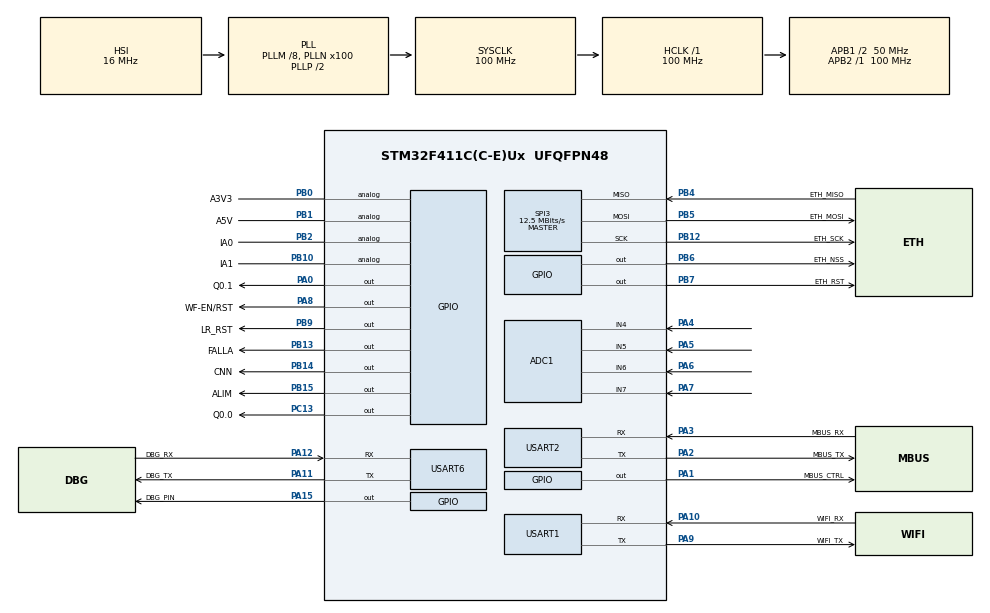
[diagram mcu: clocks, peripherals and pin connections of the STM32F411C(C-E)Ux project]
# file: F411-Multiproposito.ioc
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ADC1.Channel-0\#ChannelRegularConversion=ADC_CHANNEL_4
ADC1.NbrOfConversionFlag=1
ADC1.Rank-0\#ChannelRegularConversion=1
ADC1.SamplingTime-0\#ChannelRegularConversion=ADC_SAMPLETIME_3CYCLES
ADC1.master=1
Mcu.Family=STM32F4
Mcu.Name=STM32F411C(C-E)Ux
Mcu.Package=UFQFPN48
NVIC.PriorityGroup=NVIC_PRIORITYGROUP_4
NVIC.TIM2_IRQn=true\:0\:0\:false\:false\:true\:true\:true\:true
NVIC.TIM3_IRQn=true\:0\:0\:false\:false\:true\:true\:true\:true
NVIC.TIM4_IRQn=true\:0\:0\:false\:false\:true\:true\:true\:true
NVIC.USART1_IRQn=true\:0\:0\:false\:false\:true\:true\:true\:true
NVIC.USART2_IRQn=true\:0\:0\:false\:false\:true\:true\:true\:true
NVIC.USART6_IRQn=true\:0\:0\:false\:false\:true\:true\:true\:true
PA0-WKUP.GPIO_Label=Q0.1
PA0-WKUP.Signal=GPIO_Output
PA1.GPIO_Label=MBUS_CTRL
PA1.GPIO_ModeDefaultOutputPP=GPIO_MODE_OUTPUT_OD
PA1.GPIO_PuPd=GPIO_NOPULL
PA1.Signal=GPIO_Output
PA10.GPIO_Label=WIFI_RX
PA10.Mode=Asynchronous
PA10.Signal=USART1_RX
PA11.GPIO_Label=DBG_TX
PA11.Mode=Asynchronous
PA11.Signal=USART6_TX
PA12.GPIO_Label=DBG_RX
PA12.Mode=Asynchronous
PA12.Signal=USART6_RX
PA13.Mode=Trace_Asynchronous_SW
PA13.Signal=SYS_JTMS-SWDIO
PA14.Mode=Trace_Asynchronous_SW
PA14.Signal=SYS_JTCK-SWCLK
PA15.GPIO_Label=DBG_PIN
PA15.Signal=GPIO_Output
PA2.GPIO_Label=MBUS_TX
PA2.Mode=Asynchronous
PA2.Signal=USART2_TX
PA3.GPIO_Label=MBUS_RX
PA3.Mode=Asynchronous
PA3.Signal=USART2_RX
PA4.Signal=ADCx_IN4
PA5.Signal=ADCx_IN5
PA6.Signal=ADCx_IN6
PA7.Signal=ADCx_IN7
PA8.GPIO_Label=WF-EN/RST
PA8.Signal=GPIO_Output
PA9.GPIO_Label=WIFI_TX
PA9.Mode=Asynchronous
PA9.Signal=USART1_TX
PB0.GPIO_Label=A3V3
PB0.Signal=GPIO_Analog
PB1.GPIO_Label=A5V
PB1.Signal=GPIO_Analog
PB10.GPIO_Label=IA1
PB10.Signal=GPIO_Analog
PB12.GPIO_Label=ETH_SCK
PB12.Mode=Full_Duplex_Master
PB12.Signal=SPI3_SCK
PB13.GPIO_Label=FALLA
PB13.Signal=GPIO_Output
PB14.GPIO_Label=CNN
PB14.Signal=GPIO_Output
PB15.GPIO_Label=ALIM
PB15.Signal=GPIO_Output
PB2.GPIO_Label=IA0
PB2.Signal=GPIO_Analog
PB3.Mode=Trace_Asynchronous_SW
PB3.Signal=SYS_JTDO-SWO
PB4.GPIO_Label=ETH_MISO
PB4.Mode=Full_Duplex_Master
PB4.Signal=SPI3_MISO
PB5.GPIO_Label=ETH_MOSI
PB5.Mode=Full_Duplex_Master
PB5.Signal=SPI3_MOSI
PB6.GPIO_Label=ETH_NSS
PB6.Signal=GPIO_Output
PB7.GPIO_Label=ETH_RST
PB7.Signal=GPIO_Output
PB9.GPIO_Label=LR_RST
PB9.PinState=GPIO_PIN_RESET
PB9.Signal=GPIO_Output
PC13-ANTI_TAMP.GPIO_Label=Q0.0
PC13-ANTI_TAMP.Signal=GPIO_Output
PC14-OSC32_IN.Mode=LSE-External-Oscillator
PC14-OSC32_IN.Signal=RCC_OSC32_IN
PC15-OSC32_OUT.Mode=LSE-External-Oscillator
PC15-OSC32_OUT.Signal=RCC_OSC32_OUT
PH0\ -\ OSC_IN.Mode=HSE-External-Oscillator
PH0\ -\ OSC_IN.Signal=RCC_OSC_IN
PH1\ -\ OSC_OUT.Mode=HSE-External-Oscillator
PH1\ -\ OSC_OUT.Signal=RCC_OSC_OUT
ProjectManager.HeapSize=0x200
ProjectManager.StackSize=0x400
ProjectManager.TargetToolchain=STM32CubeIDE
RCC.48MHZClocksFreq_Value=50000000
RCC.AHBFreq_Value=100000000
RCC.APB1CLKDivider=RCC_HCLK_DIV2
RCC.APB1Freq_Value=50000000
RCC.APB1TimFreq_Value=100000000
RCC.APB2Freq_Value=100000000
RCC.APB2TimFreq_Value=100000000
RCC.CortexFreq_Value=100000000
RCC.HCLKFreq_Value=100000000
RCC.HSE_VALUE=25000000
RCC.HSI_VALUE=16000000
RCC.PLLM=8
RCC.PLLN=100
RCC.SYSCLKFreq_VALUE=100000000
RCC.SYSCLKSource=RCC_SYSCLKSOURCE_PLLCLK
RCC.VCOOutputFreq_Value=200000000
SH.ADCx_IN4.0=ADC1_IN4,IN4
SH.ADCx_IN5.0=ADC1_IN5,IN5
SH.ADCx_IN6.0=ADC1_IN6,IN6
SH.ADCx_IN7.0=ADC1_IN7,IN7
SPI3.BaudRatePrescaler=SPI_BAUDRATEPRESCALER_4
SPI3.CalculateBaudRate=12.5 MBits/s
SPI3.Direction=SPI_DIRECTION_2LINES
SPI3.Mode=SPI_MODE_MASTER
SPI3.VirtualType=VM_MASTER
TIM2.AutoReloadPreload=TIM_AUTORELOAD_PRELOAD_ENABLE
TIM2.Channel-Output\ Compare1\ No\ Output=TIM_CHANNEL_1
TIM2.OCMode_1=TIM_OCMODE_INACTIVE
TIM2.Period=20000
TIM2.Prescaler=1000
TIM3.AutoReloadPreload=TIM_AUTORELOAD_PRELOAD_ENABLE
TIM3.Channel-Output\ Compare1\ No\ Output=TIM_CHANNEL_1
TIM3.OCMode_1=TIM_OCMODE_INACTIVE
TIM3.Period=150
TIM3.Prescaler=100
TIM4.AutoReloadPreload=TIM_AUTORELOAD_PRELOAD_ENABLE
TIM4.Channel-Output\ Compare1\ No\ Output=TIM_CHANNEL_1
TIM4.OCMode_1=TIM_OCMODE_INACTIVE
TIM4.Period=150
TIM4.Prescaler=100
USART1.VirtualMode=VM_ASYNC
USART2.VirtualMode=VM_ASYNC
USART6.VirtualMode=VM_ASYNC
VP_RTC_VS_RTC_Activate.Mode=RTC_Enabled
VP_RTC_VS_RTC_Calendar.Mode=RTC_Calendar
VP_TIM2_VS_ClockSourceINT.Mode=Internal
VP_TIM2_VS_OPM.Mode=OPM_bit
VP_TIM2_VS_no_output1.Mode=Output Compare1 No Output
VP_TIM3_VS_ClockSourceINT.Mode=Internal
VP_TIM3_VS_OPM.Mode=OPM_bit
VP_TIM3_VS_no_output1.Mode=Output Compare1 No Output
VP_TIM4_VS_ClockSourceINT.Mode=Internal
VP_TIM4_VS_no_output1.Mode=Output Compare1 No Output
board=custom

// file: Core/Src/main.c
/* USER CODE BEGIN Header */
/**
  ******************************************************************************
  * @file           : main.c
  * @brief          : Main program body
  ******************************************************************************
  * @attention
  *
  * Copyright (c) 2024 STMicroelectronics.
  * All rights reserved.
  *
  * This software is licensed under terms that can be found in the LICENSE file
  * in the root directory of this software component.
  * If no LICENSE file comes with this software, it is provided AS-IS.
  *
  ******************************************************************************
  */
/* USER CODE END Header */
#include "main.h"

/* USER CODE BEGIN Includes */
#include "BKP_REG.h"
#include "string.h"
#include "stdio.h"
#include "ESP8266_Chelo.h"
#include "ModBUS_Chelo.h"
#include "STR_Chelo.h"
#include "ETH_W5100.h"
#include "http.h"
#include "string.h"
#include "RYLR896.h"
/* USER CODE END Includes */

/* USER CODE BEGIN PM */
#define ITM_Port32(n)   (*((volatile unsigned long *)(0xE0000000+4*n)))
#define UID_BASE_ADDRESS 0x1FFF7A10U
/* USER CODE END PM */

ADC_HandleTypeDef hadc1;

RTC_HandleTypeDef hrtc;

SPI_HandleTypeDef hspi3;

TIM_HandleTypeDef htim2;
TIM_HandleTypeDef htim3;
TIM_HandleTypeDef htim4;

UART_HandleTypeDef huart1;
UART_HandleTypeDef huart2;
UART_HandleTypeDef huart6;

/* USER CODE BEGIN PV */

struct LoRa lr;
struct WIFI wf;
struct W5100_SPI ETH;
struct MBUS mb_lr;
struct MBUS mb_eth;			// Instancia MODBus Ethernet
struct MBUS mb_wf;			// Instancia MODBus WiFi
struct BKP_REG NVS;

uint32_t dataRTC[20],
		 UID[3];

int		mseg=0, //conteo de milisegundos
	   	ms_ticks=0,
	   	min_ticks=0,
		MB_TOUT_ticks=0,
		ESP_ticks=0,
		wf_snd_flag_ticks=0,
		WF_SND_FLAG=0;

char EP_DATA[]="/logdata",//ENDPOINT[]="/tepelco",
	 EP_ERROR[]="/logerror",
	 EP_APROV[]="/aprovisionamiento",
	 EP_[]="/logdata";

uint16_t 	S0_get_size = 0,
			tx_mem_pointer=0,
			rx_mem_pointer=0,
			send_size=0;

uint8_t EN_UART1_TMR=0,
		EN_UART2_TMR=0,
		EN_UART6_TMR=0,
		ESP_conn=0,
		ESP_timeout=0,
		ESP_restart=0,
		ESP_HW_Init=0,
		ESP_REinit=0,			//Conteo de intentos de incializacion
		ESP_InitF=0,			//Flag de error por no encontrar la sentencia
		FLAG_UART1_WF=0,
		FLAG_UART2_485=0,
		FLAG_UART6=0,
		SYS_WEB_SERVER=0,
		SYS_WF_DEBUG_EN=1,
		SYS_DEBUG_EN=1,					//Muestra eventos de sistema  por ITM
		SYS_SPI_ETH_READ_EN=0,
		SYS_ETH_DBG_EN=0,
		SYS_saveConfigData=0,
		SYS_WIFI_UART_PASSTHROUGH=0,	//Vinvula el seria directo con el ESP8266, generando un puerto transparente
		spi_no_debug=0,
		spi_Data[64];

char	UART_RX_vect[4096],//UART_RX_vect[1024],
		UART2_RX_vect[512],
		UART6_RX_vect[4096],//UART6_RX_vect[512],
		UART_RX_vect_hld[4096],//UART_RX_vect_hld[1024],
		UART2_RX_vect_hld[1024],
		UART6_RX_vect_hld[4096],//UART6_RX_vect_hld[1024],
		CMP_VECT[]="\0",
		UART_RX_byte[2],
		UART2_RX_byte[2],
		UART6_RX_byte[2],
		APWFUID[65],
		dummyArray[20],
		post[512],
		body[512],

    	WEB_Salida[]="<!DOCTYPE html><html><body><h2>Datos salvados</h2></body></html>\r\n",

		WEB_Inicio_1[]="<!DOCTYPE html><html><body><h2>SetUp RIoT device</h2><form action=\"/192.168.4.1:80\">"
				"<p>IP SRVR</p><input type=\"number\" id=\"A\" name=\"A\" min=\"1\" max=\"254\"><input type=\"number\" id=\"B\" name=\"B\" min=\"0\" max=\"254\"><input type=\"number\" id=\"C\" name=\"C\" min=\"0\" max=\"254\"><input type=\"number\" id=\"D\" name=\"D\" min=\"1\" max=\"254\">"
				"<p>EP KEY</p><input type=\"number\" id=\"E\" name=\"E\" min=\"1\" max=\"4095\">"
				"<p>ETH IP</p><input type=\"number\" id=\"F\" name=\"F\" min=\"1\" max=\"254\"><input type=\"number\" id=\"G\" name=\"G\" min=\"0\" max=\"254\"><input type=\"number\" id=\"H\" name=\"H\" min=\"0\" max=\"254\"><input type=\"number\" id=\"I\" name=\"I\" min=\"1\" max=\"254\">"
				"<p>ETH MSK</p><input type=\"number\" id=\"J\" name=\"J\" min=\"0\" max=\"255\"><input type=\"number\" id=\"K\" name=\"K\" min=\"0\" max=\"255\"><input type=\"number\" id=\"L\" name=\"L\" min=\"0\" max=\"255\"><input type=\"number\" id=\"M\" name=\"M\" min=\"0\" max=\"255\">\r\n",

		WEB_Inicio_2[]="<p>ETH TRGT IP</p><input type=\"number\" id=\"J2\" name=\"J2\" min=\"1\" max=\"254\"><input type=\"number\" id=\"K2\" name=\"K2\" min=\"0\" max=\"254\"><input type=\"number\" id=\"L2\" name=\"L2\" min=\"0\" max=\"255\"><input type=\"number\" id=\"M2\" name=\"M2\" min=\"1\" max=\"254\">"
				"<p>ETH PRT</p><input type=\"number\" id=\"N\" name=\"N\" min=\"1\" max=\"65535\">"
				"<p>WF SSID</p><input type=\"text\" id=\"O\" name=\"O\" maxlength=\"28\" size=\"28\">"
				"<p>WF PSS</p><input type=\"password\" id=\"P\" name=\"P\" maxlength=\"12\" size=\"12\">"
				"<p>WF IP</p><input type=\"number\" id=\"Q\" name=\"Q\" min=\"1\" max=\"254\"><input type=\"number\" id=\"R\" name=\"R\" min=\"0\" max=\"255\"><input type=\"number\" id=\"S\" name=\"S\" min=\"0\" max=\"255\"><input type=\"number\" id=\"T\" name=\"T\" min=\"0\" max=\"254\">"
				"<p>WF MSK</p><input type=\"number\" id=\"U\" name=\"U\" min=\"1\" max=\"255\"><input type=\"number\" id=\"V\" name=\"V\" min=\"0\" max=\"255\"><input type=\"number\" id=\"W\" name=\"W\" min=\"0\" max=\"255\"><input type=\"number\" id=\"X\" name=\"X\" min=\"0\" max=\"255\">\r\n",

		WEB_Inicio_3[]="<p>WF PORT</p><input type=\"number\" id=\"Y\" name=\"Y\" min=\"1\" max=\"65535\">"
				"<p>MBUS REG START</p><input type=\"number\" id=\"MRS\" name=\"MRS\" min=\"0\" max=\"255\" step=\"1\" value=\"\">"
				"<p>MBUS ID Local</p><input type=\"number\" id=\"IL\" name=\"IL\" min=\"0\" max=\"255\" step=\"1\" value=\"\">"
				"<p>MBUS Code</p><input type=\"number\" id=\"MC\" name=\"MC\" min=\"3\" max=\"4\" step=\"1\" value=\"\">"
				"<p>MBUS ID SERVER</p><input type=\"number\" id=\"MIS\" name=\"MIS\" min=\"0\" max=\"255\" step=\"1\" value=\"\">"
				"<p>LoRa SRVR</p><input type=\"number\" id=\"Z\" name=\"Z\" min=\"1\" max=\"254\">"
				"<p>LoRa ADDR</p><input type=\"number\" id=\"Z2\" name=\"Z2\" min=\"1\" max=\"254\">"
				"<p>LoRa NID</p><input type=\"number\" id=\"0\" name=\"0\" min=\"0\" max=\"16\">"
				"<p>LoRa NCP</p><input type=\"number\" id=\"1\" name=\"1\" min=\"0\" max=\"16\">"
				"<p>LoRa BND</p><input type=\"number\" id=\"2\" name=\"2\" min=\"0\" max=\"55\">"
				"<input type=\"submit\" value=\"Salvar\"></form></body></html>\r\n";

		// 854 + 933 + 859

int 	dummy=0,
		dummy2=3,
		dummy3=27,
		dummy4=5,
		UART_RX_items=0,
		UART2_RX_items=0,
		UART6_RX_items=0,
		UART_RX_pos=0,
		UART2_RX_pos=0,
		UART6_RX_pos=0;

enum {
	TEPELCO,
	EFLUENTES,
	SANDBOX,
	PSEUDO,
	ESP3,
	ESP1,
	ESP2TH,
	POWERMETER,
	DISPONIBLE1,
	DISPONIBLE2,
	DISPONIBLE3,
	DISPONIBLE4,
	DISPONIBLE5,
	DISPONIBLE6,
	DISPONIBLE7,
	DISPONIBLE8,
	DISPONIBLE9,
	DISPONIBLE10
};

/* USER CODE END PV */

void SystemClock_Config(void);
static void MX_GPIO_Init(void);
static void MX_ADC1_Init(void);
static void MX_SPI3_Init(void);
static void MX_USART1_UART_Init(void);
static void MX_USART2_UART_Init(void);
static void MX_USART6_UART_Init(void);
static void MX_RTC_Init(void);
static void MX_TIM2_Init(void);
static void MX_TIM3_Init(void);
static void MX_TIM4_Init(void);

int main(void)
{

  /* USER CODE BEGIN 1 */

		//-----------------------1 Lectura de UID ------------------------//
		/* El Nro de UID se compone de 96 bits
		 * UID[0]=Coordenadas X e Y en el wafer
		 * UID[1]=Lote parcial + Nro de wafer
		 * UID[1]=Nro de Lote
		 * Por probabilidad vamos a tomar como UID a visualizar como AP los primeros 32 bits
		 */
			UID[0] = *(__IO uint32_t *)(UID_BASE_ADDRESS);
			UID[1] = *(__IO uint32_t *)(UID_BASE_ADDRESS + 4U);
			UID[2] = *(__IO uint32_t *)(UID_BASE_ADDRESS + 8U);
			INTOA(UID[0],dummyArray);
			strcpy(APWFUID,dummyArray);
			dummyArray[0]='-';
			dummyArray[1]='\0';
			strncat(APWFUID,dummyArray,strlen(dummyArray));
			dummyArray[0]='\0';
			INTOA(UID[1],dummyArray);
			strcpy(wf._WF_AP_Pass,dummyArray);
			strncat(APWFUID,dummyArray,strlen(dummyArray));
			strcpy(wf._WF_AP_SSID,"RIOT-");
			strncat(wf._WF_AP_SSID,APWFUID,strlen(APWFUID));

		//-----------------------0 Lectura de UID ------------------------//
		//----------------------1 ModBUS -----------------------//

			ModBUS_Config(&mb_lr);		//ETHERNET como cliente TCP envía  ModBUS
			mb_lr._mode = CLIENTE;
			ModBUS_Config(&mb_eth);		//ETHERNET como cliente TCP envía  ModBUS
			mb_eth._mode = CLIENTE;

		//----------------------0 ModBUS -----------------------//
		//-----------------------1 ETHERNET W5100 Environment-------------------------//

		//	GATEWAY ADDRESS
			ETH.GAR[0]=192;
			ETH.GAR[1]=168;
			ETH.GAR[2]=0;
			ETH.GAR[3]=1;
		//	SUBNET MASK
			ETH.SUBR[0]=255;
			ETH.SUBR[1]=255;
			ETH.SUBR[2]=255;
			ETH.SUBR[3]=0;
		//	MAC ADDRESS
			ETH.SHAR[0]=0x00;
			ETH.SHAR[1]=0x08;
			ETH.SHAR[2]=0xDC;
			ETH.SHAR[3]=0x00;
			ETH.SHAR[4]=0x00;
			ETH.SHAR[5]=0x01;
		//	IP ADDRESS
			ETH.SIPR[0]=192;
			ETH.SIPR[1]=168;
			ETH.SIPR[2]=0;
			ETH.SIPR[3]=34;//ETH.SIPR[3]=6,
		//  Socket RX memory
			ETH.RMSR=0x55;
		//  Socket TX memory
			ETH.TMSR=0x55;
		//  S0 Port Number
			ETH.S0_PORT[0]=0x01;
			ETH.S0_PORT[1]=0xF6;
		//	S0 Client IP ADDRESS
			ETH.S0_DIPR[0]=192;
			ETH.S0_DIPR[1]=168;
			ETH.S0_DIPR[2]=0;
			ETH.S0_DIPR[3]=3;//=3;
		//	S0 Client IP ADDRESS
			ETH.S0_DPORT[0]=0x01;
			ETH.S0_DPORT[1]=0xF6;

			ETH.gS0_RX_BASE = 0x6000;
			ETH.gS0_RX_MASK = 0x07FF;
			ETH.gS1_RX_BASE = 0x6800;
			ETH.gS1_RX_MASK = 0x07FF;
			ETH.gS2_RX_BASE = 0x7000;
			ETH.gS2_RX_MASK = 0x07FF;
			ETH.gS3_RX_BASE = 0x7800;
			ETH.gS3_RX_MASK = 0x07FF;
			ETH.gS0_TX_BASE = 0x4000;
			ETH.gS0_TX_MASK = 0x07FF;
			ETH.gS1_TX_BASE = 0x4800;
			ETH.gS1_TX_MASK = 0x07FF;
			ETH.gS2_TX_BASE = 0x5000;
			ETH.gS2_TX_MASK = 0x07FF;
			ETH.gS3_TX_BASE = 0x5800;
			ETH.gS3_TX_MASK = 0x07FF;

			ETH.S0_ENserver = 0;			//Actúa como servidor S0_ENserver=1 o cliente S0_ENserver=0

		//-----------------------0 ETHERNET W5100 Environment-------------------------//
		// -----------1 Seteo de módulo Ethernet W5100 ----------- //
			spi_no_debug=1;
			ETH.NSS_PORT=GPIOB;
			ETH.NSS_PIN=GPIO_PIN_6;
			ETH.SPI= &hspi3;
		// -----------0 Seteo de módulo Ethernet W5100 ----------- //

  /* USER CODE END 1 */

  /* MCU Configuration--------------------------------------------------------*/

  /* Reset of all peripherals, Initializes the Flash interface and the Systick. */
  HAL_Init();

  /* Configure the system clock */
  SystemClock_Config();

  /* Initialize all configured peripherals */
  MX_GPIO_Init();
  MX_ADC1_Init();
  MX_SPI3_Init();
  MX_USART1_UART_Init();
  MX_USART2_UART_Init();
  MX_USART6_UART_Init();
  MX_RTC_Init();
  MX_TIM2_Init();
  MX_TIM3_Init();
  MX_TIM4_Init();
  /* USER CODE BEGIN 2 */

  //------------------1 Habilitacion de dispositivos ---------------//

    HAL_GPIO_WritePin(GPIOB, LR_RST_Pin, GPIO_PIN_SET);		//Habilito LoRa
    HAL_GPIO_WritePin(GPIOA, MBUS_CTRL_Pin, GPIO_PIN_RESET);	//Habilito 485 para RX
    HAL_GPIO_WritePin(GPIOA, WF_EN_RST_Pin, GPIO_PIN_SET);	//Habilito WiFi
    HAL_GPIO_WritePin(GPIOB, GPIO_PIN_7, SET);				//Habilito ETHERNET

  //------------------0 Habilitacion de dispositivos ---------------//
  //------------------1 Se visualiza SSID y AP ---------------//
	ITM0_Write("\r\n\r\n\r\n SYS-uC ID :",strlen("\r\n\r\n\r\n SYS-uC ID :"));
	ITM0_Write(APWFUID,strlen(APWFUID));
	ITM0_Write( "\r\n\r\n\r\n SYS-AP-SSID :", strlen("\r\n\r\n\r\n SYS-AP-SSID :"));
	ITM0_Write( wf._WF_AP_SSID, strlen(wf._WF_AP_SSID));
	ITM0_Write( "\r\n\r\n\r\n SYS-AP-PASS : ", strlen("\r\n\r\n\r\n SYS-AP-PASS : "));
	ITM0_Write( wf._WF_AP_Pass, strlen(wf._WF_AP_Pass));
	ITM0_Write("\r\n\r\n\r\n SYS-ARRANQUE",strlen("\r\n\r\n\r\n SYS-ARRANQUE"));
	if(SYS_DEBUG_EN==1)
		{
			HAL_UART_Transmit(&huart6, "\r\n\r\n\r\n SYS-AP-SSID :", strlen("\r\n\r\n\r\n SYS-AP-SSID :"), 100);
			HAL_UART_Transmit(&huart6, wf._WF_AP_SSID, strlen(wf._WF_AP_SSID), 100);
			HAL_UART_Transmit(&huart6, "\r\n\r\n\r\n SYS-AP-PASS : ", strlen("\r\n\r\n\r\n SYS-AP-PASS : "), 100);
			HAL_UART_Transmit(&huart6, wf._WF_AP_Pass, strlen(wf._WF_AP_Pass), 100);
			HAL_UART_Transmit(&huart6, "\r\n SYS-ARRANQUE", strlen("\r\n SYS-ARRANQUE"), 100);
		}
	//------------------0 Se visualiza SSID y AP ---------------//

  //------------------1 Revisión de datos guardados en memoria ---------------//
  HAL_UART_Receive_IT(&huart1,(uint8_t *)UART_RX_byte,1);
  if(BKP_RG_BYTE(&hrtc,READ,LORA,BAND,NVS._LORA_BAND)==0)
  {
	  createAccessPoint(&wf,&huart1);
	  SYS_saveConfigData=1;
	  while(SYS_saveConfigData==1)
	  {
		  if(FLAG_UART1_WF==1)
		  {
			dummy2=strlen(":GET /192.168.4.1:80?A=");
			if(FT_String_ND(UART_RX_vect_hld,&UART_RX_items,":GET /192.168.4.1:80?A=",&dummy2,wf._uartRCVD_tok,wf._n_tok,&dummy,wf._id_conn,wf._overflowVector,FIND)==1)
				{
					BKP_AP_EXTRACT(&NVS,UART_RX_vect_hld,UART_RX_items);	//Gurado los datos ingresado por la web a la estrucutra NVS
					ITM0_Write("\r\n SYS-Escritura de valores en registros de back up",strlen("\r\n SYS-Escritura de valores en registros de back up"));
					if(SYS_DEBUG_EN==1) HAL_UART_Transmit(&huart6, "\r\n SYS-Escritura de valores en registros de back up", strlen("\r\n SYS-Escritura de valores en registros de back up"), 100);
					BKP_REG_RW(&hrtc, WRITE, &NVS);							//Salvo los datos de la estrucutra NVS en los registros de BackUp
					BKP_REG_SHW(&NVS,&huart6,SYS_DEBUG_EN);					//Muestro los datos leídos de la estructura
					if(SYS_DEBUG_EN==1)
						{
						HAL_UART_Transmit(&huart6, "\r\n SYS-Datos recibidos de AP", strlen("\r\n SYS-Datos recibidos de AP"), 100);
					    HAL_UART_Transmit(&huart1, "AT+CIPSEND=0,66\r\n", strlen("AT+CIPSEND=0,66\r\n"), 100);
					    HAL_Delay(500);
					    HAL_UART_Transmit(&huart1, WEB_Salida, strlen(WEB_Salida), 100);
						HAL_Delay(100);
						HAL_UART_Transmit(&huart1, "AT+CIPCLOSE=0\r\n", strlen("AT+CIPCLOSE=0\r\n"), 100);
						}
					SYS_saveConfigData=0;
					SYS_SPI_ETH_READ_EN=1;
					FLAG_UART1_WF=0;
				}
				else{
					  dummy2=strlen("+IPD,0,");
					  if(FT_String_ND(UART_RX_vect_hld,&UART_RX_items,"+IPD,0,",&dummy2,wf._uartRCVD_tok,wf._n_tok,&dummy,wf._id_conn,wf._overflowVector,FIND)==1)
					  {
						  //------------------------ PAGINA WEB ------------------------ //
						  HAL_UART_Transmit(&huart1, "AT+CIPSEND=0,856\r\n", strlen("AT+CIPSEND=0,856\r\n"), 100);
						  HAL_Delay(300);
						  HAL_UART_Transmit(&huart1, WEB_Inicio_1, strlen(WEB_Inicio_1), 100);
						  HAL_Delay(300);
						  HAL_UART_Transmit(&huart1, "AT+CIPSEND=0,935\r\n", strlen("AT+CIPSEND=0,935\r\n"), 100);
						  HAL_Delay(300);
						  HAL_UART_Transmit(&huart1, WEB_Inicio_2, strlen(WEB_Inicio_2), 100);
						  HAL_Delay(300);
						  HAL_UART_Transmit(&huart1, "AT+CIPSEND=0,861\r\n", strlen("AT+CIPSEND=0,861\r\n"), 100);
						  HAL_Delay(300);
						  HAL_UART_Transmit(&huart1, WEB_Inicio_3, strlen(WEB_Inicio_3), 100);
						  HAL_Delay(300);
						  HAL_UART_Transmit(&huart1, "AT+CIPCLOSE=0\r\n", strlen("AT+CIPCLOSE=0\r\n"), 100);
						  HAL_Delay(10);
						  //------------------------ PAGINA WEB ------------------------ //
						  FLAG_UART1_WF=0;
						  }else
							  {
							  FLAG_UART1_WF=0;
							  }
					}
		  }
	  }
  }
  else{
		  ITM0_Write("\r\n SYS-Lectura de valores en registros de back up",strlen("\r\n SYS-Lectura de valores en registros de back up"));
		  if(SYS_DEBUG_EN==1) HAL_UART_Transmit(&huart6, "\r\n SYS-Lectura de valores en registros de back up", strlen("\r\n SYS-Lectura de valores en registros de back up"), 100);
		  BKP_REG_RW(&hrtc, READ, &NVS);
		  BKP_REG_SHW(&NVS,&huart6,SYS_DEBUG_EN);
  	  }
  //------------------0 Revisión de datos guardados en memoria ---------------//

  //------------------1 Inicializacion UART ---------------//
  HAL_UART_Receive_IT(&huart1,(uint8_t *)UART_RX_byte,1);
  HAL_UART_Receive_IT(&huart2,(uint8_t *)UART2_RX_byte,1);
  HAL_UART_Receive_IT(&huart6,(uint8_t *)UART6_RX_byte,1);
  ITM0_Write("\r\nPuerto serie en escucha",strlen("\r\nPuerto serie en escucha"));
  if(SYS_DEBUG_EN==1) HAL_UART_Transmit(&huart6, "\r\nPuerto serie en escucha", strlen("\r\nPuerto serie en escucha"), 100);
  //------------------0 Inicializacion UART ---------------//

  //------------------1 Inicializacion ETHERNET ---------------//
  if(SYS_ETH_DBG_EN==1) ITM0_Write("\r\n SET-UP W5100 \r\n",strlen("\r\n SET-UP W5100 \r\n"));
  eth_init(&ETH);
  eth_socket_init(&ETH,0);
  SYS_SPI_ETH_READ_EN=1;
  //------------------0 Inicializacion ETHERNET ---------------//
  //------------------1 Inicializacion WIFI ---------------//

  	Inicializar(&wf); 									//Borra todos los registros de la estructura
  	wf.RESET_PORT=GPIOA;
  	wf.RESET_PIN=WF_EN_RST_Pin;
	strcpy(wf._WF_Net, NVS._WIFI_SSID);						//Nombre de la red WIFI  a conectar Fibertel WiFi967 2.4GHz
	strcpy(wf._WF_Pass, NVS._WIFI_PASS);						//Password de la red WIFI
	strcpy(wf._TCP_Remote_Server_IP, NVS._SERVER);		//char _TCP_Remote_Server_IP[16];		//IP del Servidor TCP
	strcpy(wf._TCP_Remote_Server_Port, NVS._WIFI_PORT);		//char _TCP_Remote_Server_Port[16];			//Puerto del Servidor TCP
	/*strcpy(wf._TCP_Local_Server_IP, TCP_SERVER_LOCAL);
	strcpy(wf._TCP_Local_Server_GWY, TCP_SERVER_LOCAL_GWY);
	strcpy(wf._TCP_Local_Server_MSK, TCP_SERVER_LOCAL_MSK);
	strcpy(wf._TCP_Local_Server_Port, TCP_PORT_LOCAL);*/
	wf._TCP_Local_Server_EN=0;							//Habilito el Servidor Local
	wf._estado_conexion=100;//Si no se define no arranca	//wf._estado_conexion=1;					//Arranco en WiFi Desconectado
	wf._automatizacion=WF_CONNECT_TCP;//wf._automatizacion=WF_SEND;//
	wf._NO_IP=1;
	wf._DBG_EN=1;

  if(ESP8266_HW_Init(&huart1)==1)
  {
	  ESP_HW_Init=1;
	  if (wf._DBG_EN==1) ITM0_Write("\r\n ESP HW Init OK\r\n",19);
	  if (SYS_WF_DEBUG_EN==1) HAL_UART_Transmit_IT(&huart6,"\r\n ESP HW Init OK\r\n",strlen("\r\n ESP HW Init OK\r\n"));
  }
  else
  {
	  ESP_REinit=0;
	  ESP8266_HW_Reset(&wf); 				//Si no logra resetear con el comando de AT+RESTORE, pruebo el resete desde hardware
	  if(ESP8266_HW_Init(&huart1)==1)
	  {
		  ESP_HW_Init=1;
		  if (wf._DBG_EN==1) ITM0_Write("\r\n ESP HW Init OK\r\n",19);
		  if (SYS_WF_DEBUG_EN==1) HAL_UART_Transmit_IT(&huart2,"\r\n ESP HW Init OK\r\n",strlen("\r\n ESP HW Init OK\r\n"));
	  }
	  else
	  {
		  ESP_HW_Init=0;
		  if (wf._DBG_EN==1)  ITM0_Write("\r\n ESP HW Init Fail\r\n",24);
		  if (SYS_WF_DEBUG_EN==1) HAL_UART_Transmit_IT(&huart2,"\r\n ESP HW Init Fail\r\n",strlen("\r\n ESP HW Init Fail\r\n"));
	  }
  }

  HAL_Delay(1000);
  //------------------0 Inicializacion WIFI ---------------//

  /* USER CODE END 2 */

  /* Infinite loop */
  while (1)
  {

    /* USER CODE BEGIN 3 */

	 if (ESP_restart==1) //WRNNG Hardcoded RESET WIFI
		{
			ESP8266_HW_Reset(&wf);
			ITM0_Write("\r\nESP8266 Restart",strlen("\r\nESP8266 Restart"));
		}

	 if (ESP_HW_Init==1) //Si el módulo se inició correctamente
		{
			if((WF_SND_FLAG==1)&&(wf._TCP_Local_Server_EN==0)&&(wf._estado_conexion>=609)&&(ETH.S0_data_available))
			{	ETH.S0_data_available=0;
				wf_snd_flag_ticks=0;
				WF_SND_FLAG=0;
				if( httpPOST(	EP_DATA, NVS._SERVER,NVS._WIFI_PORT,
								ModBUS_F03_Read(&mb_eth,0),
								ModBUS_F03_Read(&mb_eth,1),
								ModBUS_F03_Read(&mb_eth,2),
								ModBUS_F03_Read(&mb_eth,3),
								ModBUS_F03_Read(&mb_eth,4),
								ModBUS_F03_Read(&mb_eth,5),
								ModBUS_F03_Read(&mb_eth,6),
								ModBUS_F03_Read(&mb_eth,7),
								ModBUS_F03_Read(&mb_eth,8),
								ModBUS_F03_Read(&mb_eth,9),
								ModBUS_F03_Read(&mb_eth,10),
								ModBUS_F03_Read(&mb_eth,11),
								ModBUS_F03_Read(&mb_eth,12),
								ModBUS_F03_Read(&mb_eth,13),
								ModBUS_F03_Read(&mb_eth,14),
								ModBUS_F03_Read(&mb_eth,15),
								SANDBOX,post, body, 512))
				{
							CopiaVector(wf._data2SND,post,strlen(post),0,'A');
							wf._n_D2SND=strlen(post);
							if(wf._automatizacion < WF_SEND)		// Send only with automation sent diasabled
							{
								EnviarDatos(&wf);
								wf._estado_conexion=TCP_SND_EN_CURSO;
							}
				}
			}
		}

	  if((FLAG_UART1_WF==1)||(ESP_timeout==1))
		  {
			  if(ESP_timeout==1)
			  {
				ESP_timeout=0;
			  }
			if(FLAG_UART1_WF==1)
				{
					CopiaVector(wf._uartRCVD,UART_RX_vect_hld,UART_RX_items,1,CMP_VECT);
					FLAG_UART1_WF=0;
				}

			  ITM0_Write("\r\nRX UART1",strlen("\r\nRX UART1"));

			  if (ESP_HW_Init==1) //Si el módulo se inició correctamente
				{
					  /*************** Copio y proceso info recibida ***************/
					  wf._n_orig=UART_RX_items;
					  CopiaVector(wf._uartRCVD,UART_RX_vect_hld,UART_RX_items,1,CMP_VECT);
					  ESP_conn=AT_ESP8266_ND(&wf);

					/*************** Si recibo datos y estan correctos me fijo que son ***************/

					if ((wf._new_data_rcv==1)&&(wf._estado_rcv_data==99))
					{

						CopiaVector(mb_wf._MBUS_RCVD,wf._dataRCV,wf._n_dataRCV,0,'A');
						mb_wf._n_MBUS_RCVD=wf._n_dataRCV;

						ModBUS(&mb_wf);

						CopiaVector(wf._data2SND,mb_wf._MBUS_2SND,mb_wf._n_MBUS_2SND,0,'A');
						wf._n_D2SND=mb_wf._n_MBUS_2SND;
						wf._new_data_rcv=0;//
						wf._send_data=1;
					}else
						{
							// DATA ERRONEA NO SE PROCESA
						}
				}

			  FLAG_UART1_WF=0;
		  }
	  if (ESP_HW_Init==1) //Si el módulo se inició correctamente
		{
			ESP_conn=WiFi_Conn_ND(&wf,&huart1,1);	//Tiene que ir en el main el chequeo es constante
		}

	  if(FLAG_UART2_485==1)
	  {
		  ITM0_Write("\r\nRX UART2",strlen("\r\nRX UART2"));
		  dummy3=strlen("PRUEBA DE RECEPCION VIA 485");
		  if(FT_String_ND(UART2_RX_vect_hld,&UART2_RX_items,"PRUEBA DE RECEPCION VIA 485",&dummy3,wf._uartRCVD_tok,wf._n_tok,&dummy,wf._id_conn,wf._overflowVector,FIND)==1)
		  {
			  HAL_GPIO_WritePin(GPIOA, MBUS_CTRL_Pin, GPIO_PIN_SET);	//Habilito 485 para TX
			  HAL_UART_Transmit(&huart2,"TX VIA RS-485\r\n", 15, 100);
			  HAL_GPIO_WritePin(GPIOA, MBUS_CTRL_Pin, GPIO_PIN_RESET);	//Habilito 485 para RX
		  }
		  FLAG_UART2_485=0;
	  }

	  if(FLAG_UART6==1)
	  {
		  ITM0_Write("\r\nRX UART6",strlen("\r\nRX UART6"));
		  dummy4=strlen("+RCV");
		  if(FT_String_ND(UART6_RX_vect_hld,&UART6_RX_items,"+RCV",&dummy4,wf._uartRCVD_tok,wf._n_tok,&dummy,wf._id_conn,wf._overflowVector,FIND)==1)
		  {
			  HAL_UART_Transmit(&huart6,"AT\r\n", 4, 100);
		  }
		  FLAG_UART6=0;
	  }

  }
  /* USER CODE END 3 */
}

void SystemClock_Config(void)
{
  RCC_OscInitTypeDef RCC_OscInitStruct = {0};
  RCC_ClkInitTypeDef RCC_ClkInitStruct = {0};

  /** Configure the main internal regulator output voltage
  */
  __HAL_RCC_PWR_CLK_ENABLE();
  __HAL_PWR_VOLTAGESCALING_CONFIG(PWR_REGULATOR_VOLTAGE_SCALE1);

  /** Initializes the RCC Oscillators according to the specified parameters
  * in the RCC_OscInitTypeDef structure.
  */
  RCC_OscInitStruct.OscillatorType = RCC_OSCILLATORTYPE_HSI|RCC_OSCILLATORTYPE_LSI;
  RCC_OscInitStruct.HSIState = RCC_HSI_ON;
  RCC_OscInitStruct.HSICalibrationValue = RCC_HSICALIBRATION_DEFAULT;
  RCC_OscInitStruct.LSIState = RCC_LSI_ON;
  RCC_OscInitStruct.PLL.PLLState = RCC_PLL_ON;
  RCC_OscInitStruct.PLL.PLLSource = RCC_PLLSOURCE_HSI;
  RCC_OscInitStruct.PLL.PLLM = 8;
  RCC_OscInitStruct.PLL.PLLN = 100;
  RCC_OscInitStruct.PLL.PLLP = RCC_PLLP_DIV2;
  RCC_OscInitStruct.PLL.PLLQ = 4;
  if (HAL_RCC_OscConfig(&RCC_OscInitStruct) != HAL_OK)
  {
    Error_Handler();
  }

  /** Initializes the CPU, AHB and APB buses clocks
  */
  RCC_ClkInitStruct.ClockType = RCC_CLOCKTYPE_HCLK|RCC_CLOCKTYPE_SYSCLK
                              |RCC_CLOCKTYPE_PCLK1|RCC_CLOCKTYPE_PCLK2;
  RCC_ClkInitStruct.SYSCLKSource = RCC_SYSCLKSOURCE_PLLCLK;
  RCC_ClkInitStruct.AHBCLKDivider = RCC_SYSCLK_DIV1;
  RCC_ClkInitStruct.APB1CLKDivider = RCC_HCLK_DIV2;
  RCC_ClkInitStruct.APB2CLKDivider = RCC_HCLK_DIV1;

  if (HAL_RCC_ClockConfig(&RCC_ClkInitStruct, FLASH_LATENCY_3) != HAL_OK)
  {
    Error_Handler();
  }
}

static void MX_ADC1_Init(void)
{

  ADC_ChannelConfTypeDef sConfig = {0};

  /** Configure the global features of the ADC (Clock, Resolution, Data Alignment and number of conversion)
  */
  hadc1.Instance = ADC1;
  hadc1.Init.ClockPrescaler = ADC_CLOCK_SYNC_PCLK_DIV4;
  hadc1.Init.Resolution = ADC_RESOLUTION_12B;
  hadc1.Init.ScanConvMode = DISABLE;
  hadc1.Init.ContinuousConvMode = DISABLE;
  hadc1.Init.DiscontinuousConvMode = DISABLE;
  hadc1.Init.ExternalTrigConvEdge = ADC_EXTERNALTRIGCONVEDGE_NONE;
  hadc1.Init.ExternalTrigConv = ADC_SOFTWARE_START;
  hadc1.Init.DataAlign = ADC_DATAALIGN_RIGHT;
  hadc1.Init.NbrOfConversion = 1;
  hadc1.Init.DMAContinuousRequests = DISABLE;
  hadc1.Init.EOCSelection = ADC_EOC_SINGLE_CONV;
  if (HAL_ADC_Init(&hadc1) != HAL_OK)
  {
    Error_Handler();
  }

  /** Configure for the selected ADC regular channel its corresponding rank in the sequencer and its sample time.
  */
  sConfig.Channel = ADC_CHANNEL_4;
  sConfig.Rank = 1;
  sConfig.SamplingTime = ADC_SAMPLETIME_3CYCLES;
  if (HAL_ADC_ConfigChannel(&hadc1, &sConfig) != HAL_OK)
  {
    Error_Handler();
  }

}

static void MX_RTC_Init(void)
{

  RTC_TimeTypeDef sTime = {0};
  RTC_DateTypeDef sDate = {0};

  /** Initialize RTC Only
  */
  hrtc.Instance = RTC;
  hrtc.Init.HourFormat = RTC_HOURFORMAT_24;
  hrtc.Init.AsynchPrediv = 127;
  hrtc.Init.SynchPrediv = 255;
  hrtc.Init.OutPut = RTC_OUTPUT_DISABLE;
  hrtc.Init.OutPutPolarity = RTC_OUTPUT_POLARITY_HIGH;
  hrtc.Init.OutPutType = RTC_OUTPUT_TYPE_OPENDRAIN;
  if (HAL_RTC_Init(&hrtc) != HAL_OK)
  {
    Error_Handler();
  }

  /** Initialize RTC and set the Time and Date
  */
  sTime.Hours = 0x0;
  sTime.Minutes = 0x0;
  sTime.Seconds = 0x0;
  sTime.DayLightSaving = RTC_DAYLIGHTSAVING_NONE;
  sTime.StoreOperation = RTC_STOREOPERATION_RESET;
  if (HAL_RTC_SetTime(&hrtc, &sTime, RTC_FORMAT_BCD) != HAL_OK)
  {
    Error_Handler();
  }
  sDate.WeekDay = RTC_WEEKDAY_MONDAY;
  sDate.Month = RTC_MONTH_JANUARY;
  sDate.Date = 0x1;
  sDate.Year = 0x0;

  if (HAL_RTC_SetDate(&hrtc, &sDate, RTC_FORMAT_BCD) != HAL_OK)
  {
    Error_Handler();
  }

}

static void MX_SPI3_Init(void)
{

  /* SPI3 parameter configuration*/
  hspi3.Instance = SPI3;
  hspi3.Init.Mode = SPI_MODE_MASTER;
  hspi3.Init.Direction = SPI_DIRECTION_2LINES;
  hspi3.Init.DataSize = SPI_DATASIZE_8BIT;
  hspi3.Init.CLKPolarity = SPI_POLARITY_LOW;
  hspi3.Init.CLKPhase = SPI_PHASE_1EDGE;
  hspi3.Init.NSS = SPI_NSS_SOFT;
  hspi3.Init.BaudRatePrescaler = SPI_BAUDRATEPRESCALER_4;
  hspi3.Init.FirstBit = SPI_FIRSTBIT_MSB;
  hspi3.Init.TIMode = SPI_TIMODE_DISABLE;
  hspi3.Init.CRCCalculation = SPI_CRCCALCULATION_DISABLE;
  hspi3.Init.CRCPolynomial = 10;
  if (HAL_SPI_Init(&hspi3) != HAL_OK)
  {
    Error_Handler();
  }

}

static void MX_TIM2_Init(void)
{

  TIM_ClockConfigTypeDef sClockSourceConfig = {0};
  TIM_MasterConfigTypeDef sMasterConfig = {0};
  TIM_OC_InitTypeDef sConfigOC = {0};

  htim2.Instance = TIM2;
  htim2.Init.Prescaler = 1000;
  htim2.Init.CounterMode = TIM_COUNTERMODE_UP;
  htim2.Init.Period = 20000;
  htim2.Init.ClockDivision = TIM_CLOCKDIVISION_DIV1;
  htim2.Init.AutoReloadPreload = TIM_AUTORELOAD_PRELOAD_ENABLE;
  if (HAL_TIM_Base_Init(&htim2) != HAL_OK)
  {
    Error_Handler();
  }
  sClockSourceConfig.ClockSource = TIM_CLOCKSOURCE_INTERNAL;
  if (HAL_TIM_ConfigClockSource(&htim2, &sClockSourceConfig) != HAL_OK)
  {
    Error_Handler();
  }
  if (HAL_TIM_OC_Init(&htim2) != HAL_OK)
  {
    Error_Handler();
  }
  if (HAL_TIM_OnePulse_Init(&htim2, TIM_OPMODE_SINGLE) != HAL_OK)
  {
    Error_Handler();
  }
  sMasterConfig.MasterOutputTrigger = TIM_TRGO_RESET;
  sMasterConfig.MasterSlaveMode = TIM_MASTERSLAVEMODE_DISABLE;
  if (HAL_TIMEx_MasterConfigSynchronization(&htim2, &sMasterConfig) != HAL_OK)
  {
    Error_Handler();
  }
  sConfigOC.OCMode = TIM_OCMODE_INACTIVE;
  sConfigOC.Pulse = 0;
  sConfigOC.OCPolarity = TIM_OCPOLARITY_HIGH;
  sConfigOC.OCFastMode = TIM_OCFAST_DISABLE;
  if (HAL_TIM_OC_ConfigChannel(&htim2, &sConfigOC, TIM_CHANNEL_1) != HAL_OK)
  {
    Error_Handler();
  }

}

static void MX_TIM3_Init(void)
{

  TIM_ClockConfigTypeDef sClockSourceConfig = {0};
  TIM_MasterConfigTypeDef sMasterConfig = {0};
  TIM_OC_InitTypeDef sConfigOC = {0};

  htim3.Instance = TIM3;
  htim3.Init.Prescaler = 100;
  htim3.Init.CounterMode = TIM_COUNTERMODE_UP;
  htim3.Init.Period = 150;
  htim3.Init.ClockDivision = TIM_CLOCKDIVISION_DIV1;
  htim3.Init.AutoReloadPreload = TIM_AUTORELOAD_PRELOAD_ENABLE;
  if (HAL_TIM_Base_Init(&htim3) != HAL_OK)
  {
    Error_Handler();
  }
  sClockSourceConfig.ClockSource = TIM_CLOCKSOURCE_INTERNAL;
  if (HAL_TIM_ConfigClockSource(&htim3, &sClockSourceConfig) != HAL_OK)
  {
    Error_Handler();
  }
  if (HAL_TIM_OC_Init(&htim3) != HAL_OK)
  {
    Error_Handler();
  }
  if (HAL_TIM_OnePulse_Init(&htim3, TIM_OPMODE_SINGLE) != HAL_OK)
  {
    Error_Handler();
  }
  sMasterConfig.MasterOutputTrigger = TIM_TRGO_RESET;
  sMasterConfig.MasterSlaveMode = TIM_MASTERSLAVEMODE_DISABLE;
  if (HAL_TIMEx_MasterConfigSynchronization(&htim3, &sMasterConfig) != HAL_OK)
  {
    Error_Handler();
  }
  sConfigOC.OCMode = TIM_OCMODE_INACTIVE;
  sConfigOC.Pulse = 0;
  sConfigOC.OCPolarity = TIM_OCPOLARITY_HIGH;
  sConfigOC.OCFastMode = TIM_OCFAST_DISABLE;
  if (HAL_TIM_OC_ConfigChannel(&htim3, &sConfigOC, TIM_CHANNEL_1) != HAL_OK)
  {
    Error_Handler();
  }

}

static void MX_TIM4_Init(void)
{

  TIM_ClockConfigTypeDef sClockSourceConfig = {0};
  TIM_MasterConfigTypeDef sMasterConfig = {0};
  TIM_OC_InitTypeDef sConfigOC = {0};

  htim4.Instance = TIM4;
  htim4.Init.Prescaler = 100;
  htim4.Init.CounterMode = TIM_COUNTERMODE_UP;
  htim4.Init.Period = 150;
  htim4.Init.ClockDivision = TIM_CLOCKDIVISION_DIV1;
  htim4.Init.AutoReloadPreload = TIM_AUTORELOAD_PRELOAD_ENABLE;
  if (HAL_TIM_Base_Init(&htim4) != HAL_OK)
  {
    Error_Handler();
  }
  sClockSourceConfig.ClockSource = TIM_CLOCKSOURCE_INTERNAL;
  if (HAL_TIM_ConfigClockSource(&htim4, &sClockSourceConfig) != HAL_OK)
  {
    Error_Handler();
  }
  if (HAL_TIM_OC_Init(&htim4) != HAL_OK)
  {
    Error_Handler();
  }
  sMasterConfig.MasterOutputTrigger = TIM_TRGO_RESET;
  sMasterConfig.MasterSlaveMode = TIM_MASTERSLAVEMODE_DISABLE;
  if (HAL_TIMEx_MasterConfigSynchronization(&htim4, &sMasterConfig) != HAL_OK)
  {
    Error_Handler();
  }
  sConfigOC.OCMode = TIM_OCMODE_INACTIVE;
  sConfigOC.Pulse = 0;
  sConfigOC.OCPolarity = TIM_OCPOLARITY_HIGH;
  sConfigOC.OCFastMode = TIM_OCFAST_DISABLE;
  if (HAL_TIM_OC_ConfigChannel(&htim4, &sConfigOC, TIM_CHANNEL_1) != HAL_OK)
  {
    Error_Handler();
  }

}

static void MX_USART1_UART_Init(void)
{

  huart1.Instance = USART1;
  huart1.Init.BaudRate = 115200;
  huart1.Init.WordLength = UART_WORDLENGTH_8B;
  huart1.Init.StopBits = UART_STOPBITS_1;
  huart1.Init.Parity = UART_PARITY_NONE;
  huart1.Init.Mode = UART_MODE_TX_RX;
  huart1.Init.HwFlowCtl = UART_HWCONTROL_NONE;
  huart1.Init.OverSampling = UART_OVERSAMPLING_16;
  if (HAL_UART_Init(&huart1) != HAL_OK)
  {
    Error_Handler();
  }

}

static void MX_USART2_UART_Init(void)
{

  huart2.Instance = USART2;
  huart2.Init.BaudRate = 115200;
  huart2.Init.WordLength = UART_WORDLENGTH_8B;
  huart2.Init.StopBits = UART_STOPBITS_1;
  huart2.Init.Parity = UART_PARITY_NONE;
  huart2.Init.Mode = UART_MODE_TX_RX;
  huart2.Init.HwFlowCtl = UART_HWCONTROL_NONE;
  huart2.Init.OverSampling = UART_OVERSAMPLING_16;
  if (HAL_UART_Init(&huart2) != HAL_OK)
  {
    Error_Handler();
  }

}

static void MX_USART6_UART_Init(void)
{

  huart6.Instance = USART6;
  huart6.Init.BaudRate = 115200;
  huart6.Init.WordLength = UART_WORDLENGTH_8B;
  huart6.Init.StopBits = UART_STOPBITS_1;
  huart6.Init.Parity = UART_PARITY_NONE;
  huart6.Init.Mode = UART_MODE_TX_RX;
  huart6.Init.HwFlowCtl = UART_HWCONTROL_NONE;
  huart6.Init.OverSampling = UART_OVERSAMPLING_16;
  if (HAL_UART_Init(&huart6) != HAL_OK)
  {
    Error_Handler();
  }

}

static void MX_GPIO_Init(void)
{
  GPIO_InitTypeDef GPIO_InitStruct = {0};

  /* GPIO Ports Clock Enable */
  __HAL_RCC_GPIOC_CLK_ENABLE();
  __HAL_RCC_GPIOH_CLK_ENABLE();
  __HAL_RCC_GPIOA_CLK_ENABLE();
  __HAL_RCC_GPIOB_CLK_ENABLE();

  /*Configure GPIO pin Output Level */
  HAL_GPIO_WritePin(Q0_0_GPIO_Port, Q0_0_Pin, GPIO_PIN_RESET);

  /*Configure GPIO pin Output Level */
  HAL_GPIO_WritePin(GPIOA, Q0_1_Pin|MBUS_CTRL_Pin|WF_EN_RST_Pin|DBG_PIN_Pin, GPIO_PIN_RESET);

  /*Configure GPIO pin Output Level */
  HAL_GPIO_WritePin(GPIOB, FALLA_Pin|CNN_Pin|ALIM_Pin|ETH_NSS_Pin
                          |ETH_RST_Pin|LR_RST_Pin, GPIO_PIN_RESET);

  /*Configure GPIO pin : Q0_0_Pin */
  GPIO_InitStruct.Pin = Q0_0_Pin;
  GPIO_InitStruct.Mode = GPIO_MODE_OUTPUT_PP;
  GPIO_InitStruct.Pull = GPIO_NOPULL;
  GPIO_InitStruct.Speed = GPIO_SPEED_FREQ_LOW;
  HAL_GPIO_Init(Q0_0_GPIO_Port, &GPIO_InitStruct);

  /*Configure GPIO pins : Q0_1_Pin WF_EN_RST_Pin DBG_PIN_Pin */
  GPIO_InitStruct.Pin = Q0_1_Pin|WF_EN_RST_Pin|DBG_PIN_Pin;
  GPIO_InitStruct.Mode = GPIO_MODE_OUTPUT_PP;
  GPIO_InitStruct.Pull = GPIO_NOPULL;
  GPIO_InitStruct.Speed = GPIO_SPEED_FREQ_LOW;
  HAL_GPIO_Init(GPIOA, &GPIO_InitStruct);

  /*Configure GPIO pin : MBUS_CTRL_Pin */
  GPIO_InitStruct.Pin = MBUS_CTRL_Pin;
  GPIO_InitStruct.Mode = GPIO_MODE_OUTPUT_OD;
  GPIO_InitStruct.Pull = GPIO_NOPULL;
  GPIO_InitStruct.Speed = GPIO_SPEED_FREQ_LOW;
  HAL_GPIO_Init(MBUS_CTRL_GPIO_Port, &GPIO_InitStruct);

  /*Configure GPIO pins : A3V3_Pin A5V_Pin IA0_Pin IA1_Pin */
  GPIO_InitStruct.Pin = A3V3_Pin|A5V_Pin|IA0_Pin|IA1_Pin;
  GPIO_InitStruct.Mode = GPIO_MODE_ANALOG;
  GPIO_InitStruct.Pull = GPIO_NOPULL;
  HAL_GPIO_Init(GPIOB, &GPIO_InitStruct);

  /*Configure GPIO pins : FALLA_Pin CNN_Pin ALIM_Pin ETH_NSS_Pin
                           ETH_RST_Pin LR_RST_Pin */
  GPIO_InitStruct.Pin = FALLA_Pin|CNN_Pin|ALIM_Pin|ETH_NSS_Pin
                          |ETH_RST_Pin|LR_RST_Pin;
  GPIO_InitStruct.Mode = GPIO_MODE_OUTPUT_PP;
  GPIO_InitStruct.Pull = GPIO_NOPULL;
  GPIO_InitStruct.Speed = GPIO_SPEED_FREQ_LOW;
  HAL_GPIO_Init(GPIOB, &GPIO_InitStruct);

}

/* USER CODE BEGIN 4 */

void SysTick_Handler(void)
{
  /* USER CODE BEGIN SysTick_IRQn 0 */
   mseg++;
   ms_ticks++;
   ESP_ticks++;

	if (mseg==500)
		{
		   HAL_GPIO_TogglePin(GPIOB, FALLA_Pin);
		   HAL_GPIO_TogglePin(GPIOB, CNN_Pin);
		   HAL_GPIO_TogglePin(GPIOB, ALIM_Pin);
		   mseg=0;
		}

	if(mb_eth._w_answer) MB_TOUT_ticks++;
	if ( mb_eth._w_answer && (mb_eth._timeout < MB_TOUT_ticks))
		{
			mb_eth._w_answer=0;
			MB_TOUT_ticks=0;
		}
	// ENVIO DATOS WF ---------------------------------------------------------------//

		if((wf._estado_conexion==609 || wf._estado_conexion==700)&&(wf._TCP_Local_Server_EN==0))  wf_snd_flag_ticks++;

		if(wf_snd_flag_ticks>=4000 && wf._ejecucion!=1 && wf._TCP_Local_Server_EN==0)
			{
			WF_SND_FLAG=1;		//Envío de datos cada 20 segs
			}

	// ENVIO DATOS WF ----------------------------------- ---------------------------//

	/**********************[ INICIO - EHTERNET WDG ] **********************/

		if(ETH.S0_status == 0)
		{
			ETH.ETH_WDG++;
			if (ETH.ETH_WDG>=64000) ETH.ETH_WDG=64000;		//Si alcanza valor límite lo dejo en 64000
		}

	/**********************[ FIN 	- EHTERNET WDG ] **********************/
   if (ms_ticks==300)
     {
   	ms_ticks=0;
   	min_ticks++;

   	HAL_GPIO_TogglePin(GPIOC, GPIO_PIN_13);

   	if(spi_no_debug)
   	  {
   	  if(SYS_SPI_ETH_READ_EN==1)
   	  {
   		 HAL_GPIO_TogglePin(GPIOA, DBG_PIN_Pin);
   	     ETH.S0_status=eth_rd_SOCKET_STAT(&ETH,0);

   		  switch(ETH.S0_status)	//Check Socket status
   	     {
   			 case SOCK_CLOSED :
   				 {
   					 if (SYS_ETH_DBG_EN == 1) {ITM0_Write("\r\nS0_SOCK_CLOSED \r\n",strlen("\r\nS0_SOCK_CLOSED \r\n"));}
   					 eth_wr_SOCKET_CMD(&ETH, 0 ,OPEN );
   					 // Si no tengo intento de ARP por 5 segundos vuelvo a inicializar
   					 if(ETH.ETH_WDG>=5000)
   					 {
   						 ETH.ETH_WDG=0;
   						 eth_init(&ETH);
   						 eth_socket_init(&ETH,0);
   					 }

   				 }
   			 break;
   			 case  SOCK_INIT :
   				 {
   					 if(ETH.S0_ENserver == 1)
   					 {
   						 if (SYS_ETH_DBG_EN == 1) {ITM0_Write("\r\nS0_SOCK_INIT \r\n",strlen("\r\nS0_SOCK_INIT \r\n"));}
   							eth_wr_SOCKET_CMD(&ETH, 0, LISTEN );
   							ETH.ETH_WDG=0;
   					 }
   					 else
   					 {
   						 	eth_wr_SOCKET_CMD(&ETH,0, CONNECT);																				//only for server
   						 	if (SYS_ETH_DBG_EN == 1)
   						 	{
   						 		ITM0_Write("\r\nETH-W5100-CONNECT\r\n",strlen("\r\nETH-W5100-CONNECT\r\n"));
   						 	}
   						 	ETH.ETH_WDG=0;
   					 }

   				 }
   			 break;
   			 case SOCK_LISTEN :
   				 {
   					 if (SYS_ETH_DBG_EN == 1) {ITM0_Write("\r\nS0_SOCK_LISTEN \r\n",strlen("\r\nS0_SOCK_LISTEN \r\n"));}
   					 ETH.ETH_WDG=0;
   				 }
   			 break;
   			 case SOCK_SYNSENT :
   				 {
   					 if (SYS_ETH_DBG_EN == 1) {ITM0_Write("\r\nS0_SOCK_SYNSENT \r\n",strlen("\r\nS0_SOCK_SYNSENT \r\n"));}
   					 ETH.ETH_WDG=0;
   				 }
   			 break;
   			 case SOCK_SYNRECV :
   				 {
   					 if (SYS_ETH_DBG_EN == 1) {ITM0_Write("\r\nS0_SOCK_SYNRECV \r\n",strlen("\r\nS0_SOCK_SYNRECV \r\n"));}
   					 ETH.ETH_WDG=0;
   				 }
   			 break;
   			 case SOCK_ESTABLISHED :
   				 {
   					 if (SYS_ETH_DBG_EN == 1) {ITM0_Write("\r\nS0_SOCK_ESTABLISHED \r\n",strlen("\r\nS0_SOCK_ESTABLISHED \r\n"));}
   					 ETH.ETH_WDG=0;

   					if (ETH.S0_ENserver == 1)  // Si el puerto Ethernet actúa como server (Recibe datos conexión mas pedido mbus
   					{

   							S0_get_size = SPI_ETH_REG(&ETH, S0_RX_SZ_ADDR_BASEHH,S0_RX_SZ_ADDR_BASEHL ,SPI_READ, spi_Data,2);
   							if(S0_get_size != 0x00)
   							{
   								eth_rd_SOCKET_DATA(&ETH,0,&rx_mem_pointer,S0_get_size); // read socket data
   								SPI_ETH_WR_REG_16(&ETH,S0_RX_RD0,rx_mem_pointer );		// write rx memory pointer
   								eth_wr_SOCKET_CMD(&ETH,0,RECV);							// write command to execute
   								while(eth_rd_SOCKET_CMD(&ETH,0))						// wait until end of command execution
   								{}

   								CopiaVector(mb_eth._MBUS_RCVD, ETH.data, S0_get_size, 0, 0 );
   								mb_eth._n_MBUS_RCVD=S0_get_size;

   								//if(S0_get_size > 0)	{ ETH.S0_data_available=1;}					//Flag data received

   								if(ModBUS_Check(mb_eth._MBUS_RCVD, mb_eth._n_MBUS_RCVD))		//Ckecks ModBUS type data
   								{
   									ModBUS(&mb_eth);										//ModBUS protocol execution
   									CopiaVector(ETH.data, mb_eth._MBUS_2SND, mb_eth._n_MBUS_2SND, 0, 0);
   								}
   								else
   								{
   									if (SYS_ETH_DBG_EN == 1) {ITM0_Write("\r\n NO MBUS \r\n",strlen("\r\n\r\n NO MBUS \r\n\r\n"));}
   								}

   								send_size=mb_eth._n_MBUS_2SND;  //ModBUS data qty

   								eth_wr_SOCKET_DATA(&ETH,0, &tx_mem_pointer, send_size);	// write socket data
   								SPI_ETH_WR_REG_16(&ETH,0x424,tx_mem_pointer);			// write tx memory pointer
   								eth_wr_SOCKET_CMD(&ETH,0,SEND);							// write command to execute
   								while(eth_rd_SOCKET_CMD(&ETH,0))						// wait until end of command execution
   								{}

   							}
   					}
   					else	// Puerto ethernet labura como esclavo, se conecta al server para pedir datos
   					{

   						if (mb_eth._w_answer==0)
   						{
   							//Si ya envié vuelvo a enviar

   							ETH.data[0]=0x00;
   							ETH.data[1]=0x00;
   							ETH.data[2]=0x00;
   							ETH.data[3]=0x00;
   							ETH.data[4]=0x00;
   							ETH.data[5]=0x06;
   							ETH.data[6]=0x01;
   							ETH.data[7]=0x03;
   							ETH.data[8]=0x00;
   							ETH.data[9]=0x00;
   							ETH.data[10]=0x00;
   							ETH.data[11]=0x0A;
   							send_size=12;

   							ModBUS_F03_Request(&mb_eth,0,15);
   							CopiaVector(ETH.data, mb_eth._MBUS_2SND, 12, 0, 0 );

   							eth_wr_SOCKET_DATA(&ETH,0, &tx_mem_pointer, send_size);	// write socket data
   							SPI_ETH_WR_REG_16(&ETH,0x424,tx_mem_pointer);			// write tx memory pointer
   							eth_wr_SOCKET_CMD(&ETH,0,SEND);							// write command to execute
   							while(eth_rd_SOCKET_CMD(&ETH,0))						// wait until end of command execution
   							{}
   							mb_eth._w_answer=1;	// Waiting answer flag
   							MB_TOUT_ticks=0;	// restart counting
   							if (SYS_ETH_DBG_EN == 1) {ITM0_Write("\r\n SENT MBUS REQ \r\n",strlen("\r\n\r\n SENT MBUS REQ \r\n\r\n"));}
   						}
   						else
   						{
   						S0_get_size = SPI_ETH_REG(&ETH, S0_RX_SZ_ADDR_BASEHH,S0_RX_SZ_ADDR_BASEHL ,SPI_READ, spi_Data,2);
   							if(S0_get_size != 0x00)
   							{
   								eth_rd_SOCKET_DATA(&ETH,0,&rx_mem_pointer,S0_get_size); // read socket data
   								SPI_ETH_WR_REG_16(&ETH,S0_RX_RD0,rx_mem_pointer );		// write rx memory pointer
   								eth_wr_SOCKET_CMD(&ETH,0,RECV);							// write command to execute
   								while(eth_rd_SOCKET_CMD(&ETH,0))						// wait until end of command execution
   								{}

   								CopiaVector(mb_eth._MBUS_RCVD, ETH.data, S0_get_size, 0, 0 );
   								mb_eth._n_MBUS_RCVD=S0_get_size;

   								//if(S0_get_size > 0)	{ ETH.S0_data_available=1;}

   								if(ModBUS_Check(mb_eth._MBUS_RCVD, mb_eth._n_MBUS_RCVD))		//Ckecks ModBUS type data
   									{
   										mb_eth._w_answer=0;  									//Si el mensaje recibido ya es modbus digo que ya recibi
   										MB_TOUT_ticks=0;
   										ModBUS(&mb_eth);										//ModBUS protocol execution
   										CopiaVector(ETH.swap, mb_eth._MBUS_RCVD, mb_eth._n_MBUS_RCVD, 0, 0);
   										CopiaVector(mb_wf._Holding_Registers, mb_eth._Holding_Registers, 64, 0, 0);
   										ETH.S0_data_available=1;	//Informa que se ha recibido un dato y es ModBUS
   										if (SYS_ETH_DBG_EN == 1)
   										{
   											HAL_UART_Transmit_IT(&huart2,"\r\nMBUS RCVD\r\n",strlen("\r\nMBUS RCVD\r\n"));
   											ITM0_Write("\r\n RCVD MBUS REQ \r\n",strlen("\r\n\r\n RCVD MBUS REQ \r\n\r\n"));
   										}
   									}
   									else
   										{
   										if (SYS_ETH_DBG_EN == 1) {ITM0_Write("\r\n NO MBUS \r\n",strlen("\r\n\r\n NO MBUS \r\n\r\n"));}
   										}

   							}
   						}
   					}
   				 }
   			 break;
   			 case SOCK_FIN_WAIT :
   				 {
   					 if (SYS_ETH_DBG_EN == 1) {ITM0_Write("\r\nS0_SOCK_FIN_WAIT \r\n",strlen("\r\nS0_SOCK_FIN_WAIT \r\n"));}
   					 ETH.ETH_WDG=0;
   				 }
   			 break;
   			 case SOCK_CLOSING :
   				 {
   					 if (SYS_ETH_DBG_EN == 1) {ITM0_Write("\r\nS0_SOCK_CLOSING \r\n",strlen("\r\nS0_SOCK_CLOSING \r\n"));}
   					 ETH.ETH_WDG=0;
   				 }
   			 break;
   			 case  SOCK_TIME_WAIT :
   				 {
   					 if (SYS_ETH_DBG_EN == 1) {ITM0_Write("\r\nS0_SOCK_TIME_WAIT \r\n",strlen("\r\nS0_SOCK_TIME_WAIT \r\n"));}
   					eth_wr_SOCKET_CMD(&ETH,0, DISCON );
   					while( SPI_ETH_REG(&ETH, S0_CR_ADDR_BASEH,S0_CR_ADDR_BASEL ,SPI_READ, spi_Data,1))
   					{}
   					ETH.ETH_WDG=0;
   				 }
   			 break;
   			 case SOCK_CLOSE_WAIT :
   				 {
   					 if (SYS_ETH_DBG_EN == 1) {ITM0_Write("\r\nS0_SOCK_CLOSE_WAIT \r\n",strlen("\r\nS0_SOCK_CLOSE_WAIT \r\n"));}
   					eth_wr_SOCKET_CMD(&ETH,0,DISCON );
   					while( SPI_ETH_REG(&ETH, S0_CR_ADDR_BASEH,S0_CR_ADDR_BASEL ,SPI_READ, spi_Data,1))
   					{}
   					ETH.ETH_WDG=0;
   				 }
   			 break;
   			 case SOCK_LAST_ACK :
   				 {
   					 if (SYS_ETH_DBG_EN == 1)
   					 {
   						 ITM0_Write("\r\nS0_SOCK_LAST_ACK \r\n",strlen("\r\nS0_SOCK_LAST_ACK \r\n"));
   					 }
   					 ETH.ETH_WDG=0;
   				 }
   			 break;
   			 case SOCK_UDP :
   				 {
   					 if (SYS_ETH_DBG_EN == 1){ ITM0_Write("\r\nS0_SOCK_UDP \r\n",strlen("\r\nS0_SOCK_UDP \r\n"));}
   					 ETH.ETH_WDG=0;
   				 }
   			 break;
   			 case  SOCK_IPRAW :
   				 {
   					 if (SYS_ETH_DBG_EN == 1) {ITM0_Write("\r\nS0_SOCK_IPRAW \r\n",strlen("\r\nS0_SOCK_IPRAW \r\n"));}
   					 ETH.ETH_WDG=0;
   				 }
   			 break;
   			 case  SOCK_MACRAW :
   				 {
   					 if (SYS_ETH_DBG_EN == 1) {ITM0_Write("\r\nS0_SOCK_MACRAW \r\n",strlen("\r\nS0_SOCK_MACRAW \r\n"));}
   					 ETH.ETH_WDG=0;
   				 }
   			 break;
   			 case SOCK_PPOE :
   				 {
   					 if (SYS_ETH_DBG_EN == 1) {ITM0_Write("\r\nS0_SOCK_PPOE \r\n",strlen("\r\nS0_SOCK_PPOE \r\n"));}
   					 ETH.ETH_WDG=0;
   				 }
   			 break;

   			 default:
   				 {

   				 }
   	     }
   	  }
   	  }else
   	  	  {
   		  SPI_ETH(&ETH);
   	  	  }
   	  if(min_ticks==2)//if(min_ticks==10)
   		  {
   		  	  min_ticks=0;  /* SETEO CADA 2 min*/
   		  }
     }
  /* USER CODE END SysTick_IRQn 0 */
  HAL_IncTick();
  /* USER CODE BEGIN SysTick_IRQn 1 */
	if(wf._estado_conexion==4)//Solo cuento cuando no estahaciendo otra cosa
	{
		//ticks++;
	}
	else
	{
		//ticks=0;
	}

if(wf._ejecucion==1)
	{
		if (ESP_timeout!=1)
		{
			if(wf._instruccion!=2) wf._ticks++;//-----------------------Solo cuento una vez reconcido el timeout, cuando entro al timeout no cuento
			if(wf._instruccion==2) wf._ticks2++;
		}

		if ((wf._instruccion!=2)&&(wf._ticks > 5500)) //if (wf._ticks > 5000)
		{
			ESP_timeout=1;
			if(huart1.Instance->CR1 == 0x200C)  //--------------------Evito error UART colgado
			{
				HAL_UART_Receive_IT(&huart1,(uint8_t *)UART_RX_byte,1);
				FLAG_UART1_WF=0; //OBS-VER Para que me vuelva a habilitar el timer
			}
		}
		if ((wf._instruccion==2)&&(wf._ticks2 > 20500)) //if (wf._ticks > 5000)
		{
			ESP_timeout=1;
			if(huart1.Instance->CR1 == 0x200C)  //--------------------Evito error UART colgado
			{
				HAL_UART_Receive_IT(&huart1,(uint8_t *)UART_RX_byte,1);
				FLAG_UART1_WF=0; //OBS-VER Para que me vuelva a habilitar el timer
			}
		}

	}
	else
	{
		wf._ticks=0;
	}
  /* USER CODE END SysTick_IRQn 1 */
}

void HAL_UART_RxCpltCallback(UART_HandleTypeDef *INTSERIE)
{

// WiFi	USART 1 TIMER2
	if(INTSERIE->Instance==USART1)
		 {
			UART_RX_vect[UART_RX_pos]=UART_RX_byte[0];
			UART_RX_pos++;
			//if(UART_RX_pos>=1022) UART_RX_pos=1022;
			if(UART_RX_pos>=4095) UART_RX_pos=4095;
			HAL_TIM_OC_Start_IT(&htim2, TIM_CHANNEL_1);//HAL_TIM_Base_Start_IT(&htim7);	//Habilito el timer
			TIM2->CNT=1;
			EN_UART1_TMR=1;	//Habilito Timeout de software
			HAL_UART_Receive_IT(INTSERIE,(uint8_t *)UART_RX_byte,1);
		 }
// MBUS USART2 TIMER3
	if(INTSERIE->Instance==USART2)
		 {
			UART2_RX_vect[UART2_RX_pos]=UART2_RX_byte[0];
			UART2_RX_pos++;
			if(UART2_RX_pos>=512) UART2_RX_pos=512;
			HAL_TIM_OC_Start_IT(&htim3, TIM_CHANNEL_1);//HAL_TIM_Base_Start_IT(&htim7);	//Habilito el timer
			TIM3->CNT=1;
			EN_UART2_TMR=1;	//Habilito Timeout de software
			HAL_UART_Receive_IT(INTSERIE,(uint8_t *)UART2_RX_byte,1);
		 }
// LoRa/debgg USART6 TIMER3
	if(INTSERIE->Instance==USART6)
		 {
			UART6_RX_vect[UART6_RX_pos]=UART6_RX_byte[0];
			UART6_RX_pos++;
			//if(UART6_RX_pos>=512) UART6_RX_pos=512;
			if(UART6_RX_pos>=4095) UART6_RX_pos=4095;
			HAL_TIM_OC_Start_IT(&htim4, TIM_CHANNEL_1);//HAL_TIM_Base_Start_IT(&htim7);	//Habilito el timer
			TIM4->CNT=1;
			EN_UART6_TMR=1;	//Habilito Timeout de software
			HAL_UART_Receive_IT(INTSERIE,(uint8_t *)UART6_RX_byte,1);
		 }
 }

void HAL_TIM_OC_DelayElapsedCallback(TIM_HandleTypeDef *TIMER)
{
// WiFi	USART 1 TIMER2
		if(TIMER->Instance==TIM2)
			{
				 HAL_TIM_OC_Stop_IT(TIMER, TIM_CHANNEL_1); //Paro el timer
				 FLAG_UART1_WF=1;
				 EN_UART1_TMR=0;
				 UART_RX_items=UART_RX_pos;
				 UART_RX_pos=0;
				 UART_RX_vect[4095]='\0';//UART_RX_vect[1022]='\0'; //Finalizo el vector a la fuerza ya que recibo hasta 124
				 CopiaVector(UART_RX_vect_hld,UART_RX_vect,UART_RX_items,1,CMP_VECT);
				 if(SYS_WIFI_UART_PASSTHROUGH==1) HAL_UART_Transmit_IT(&huart6, UART_RX_vect_hld, UART_RX_items);	//Reenvío la info a traves de UART6 solo si esta habilitado
				 HAL_UART_Receive_IT(&huart1,(uint8_t *)UART_RX_byte,1); //Habilito le recepcón de puerto serie al terminar
				 if (wf._DBG_EN==1)
				 {
					 ITM0_Write("\r\nData WIFI recibida = ",strlen("\r\nData WIFI recibida = "));
					 ITM0_Write((uint8_t *)UART_RX_vect_hld,UART_RX_items);
					 ITM0_Write("\r\n",strlen("\r\n"));
				 }
		}
// MBUS USART2 TIMER3
		if(TIMER->Instance==TIM3)
			{
				 HAL_TIM_OC_Stop_IT(TIMER, TIM_CHANNEL_1); //Paro el timer
				 HAL_GPIO_WritePin(GPIOA, GPIO_PIN_1, 0);
				 FLAG_UART2_485=1;
				 EN_UART2_TMR=0;
				 UART2_RX_items=UART2_RX_pos;
				 UART2_RX_pos=0;
				 UART2_RX_vect[512]='\0'; //Finalizo el vector a la fuerza ya que recibo hasta 124
				 CopiaVector(UART2_RX_vect_hld,UART2_RX_vect,UART2_RX_items,1,CMP_VECT);
				 HAL_UART_Receive_IT(&huart2,(uint8_t *)UART2_RX_byte,1); //Habilito le recepcón de puerto serie al terminar
				 if (wf._DBG_EN==1)
				 {
					 ITM0_Write("\r\nData MBUS recibida = ",strlen("\r\nData MUS recibida = "));
					 ITM0_Write((uint8_t *)UART2_RX_vect,UART2_RX_items);
					 ITM0_Write("\r\n",strlen("\r\n"));
				 }
		}

// LoRa/Debbg USART6 TIMER3
		if(TIMER->Instance==TIM4)
			{
				 HAL_TIM_OC_Stop_IT(TIMER, TIM_CHANNEL_1); //Paro el timer
				 HAL_GPIO_WritePin(GPIOA, GPIO_PIN_1, 0);
				 FLAG_UART6=1;
				 EN_UART6_TMR=0;
				 UART6_RX_items=UART6_RX_pos;
				 UART6_RX_pos=0;
				 UART6_RX_vect[4095]='\0'; //UART6_RX_vect[512]='\0'; //Finalizo el vector a la fuerza ya que recibo hasta 124
				 CopiaVector(UART6_RX_vect_hld,UART6_RX_vect,UART6_RX_items,1,CMP_VECT);
				 if(SYS_WIFI_UART_PASSTHROUGH==1) HAL_UART_Transmit_IT(&huart1, UART6_RX_vect_hld, UART6_RX_items);	//Reenvío la info a traves de UART1 solo si esta habilitado
				 HAL_UART_Receive_IT(&huart6,(uint8_t *)UART6_RX_byte,1); //Habilito le recepcón de puerto serie al terminar
				 if (wf._DBG_EN==1)
				 {
					 ITM0_Write("\r\nData LoRa recibida = ",strlen("\r\nData LoRa recibida = "));
					 ITM0_Write((uint8_t *)UART6_RX_vect,UART6_RX_items);
					 ITM0_Write("\r\n",strlen("\r\n"));
				 }
		}
}

void HAL_UART_ErrorCallback(UART_HandleTypeDef *ERRUART)

{
	if(ERRUART->Instance==USART1)
	{
		 volatile int aore=0;
		 volatile int bore=0;
		//Al leer los registros de esta forma SR y luego DR se resetean los errores de Framing Noise y Overrun FE NE ORE
		 aore=ERRUART->Instance->SR;
		 bore=ERRUART->Instance->DR;
		 HAL_UART_DeInit(ERRUART);
		 MX_USART1_UART_Init();
		 HAL_UART_Receive_IT(ERRUART,(uint8_t *)UART_RX_byte,1);
	}
	if(ERRUART->Instance==USART2)
	{
		 volatile int aore=0;
		 volatile int bore=0;
		//Al leer los registros de esta forma SR y luego DR se resetean los errores de Framing Noise y Overrun FE NE ORE
		 aore=ERRUART->Instance->SR;
		 bore=ERRUART->Instance->DR;
		 HAL_UART_DeInit(ERRUART);
		 MX_USART2_UART_Init();
		 HAL_UART_Receive_IT(ERRUART,(uint8_t *)UART2_RX_byte,1);
	}
	if(ERRUART->Instance==USART6)
	{
		 volatile int aore=0;
		 volatile int bore=0;
		//Al leer los registros de esta forma SR y luego DR se resetean los errores de Framing Noise y Overrun FE NE ORE
		 aore=ERRUART->Instance->SR;
		 bore=ERRUART->Instance->DR;
		 HAL_UART_DeInit(ERRUART);
		 MX_USART6_UART_Init();
		 HAL_UART_Receive_IT(ERRUART,(uint8_t *)UART6_RX_byte,1);
	}

}

int ESP8266_HW_Init(UART_HandleTypeDef *SerialPort) //Devuelve 1 si reinició OK, y 0 si no
{
	do{
		  HAL_UART_Transmit(SerialPort, "AT+RESTORE\r\n",12,100);
		  HAL_Delay(500);
		  wf._n_fcomp=5;			//Cdad de elementos del vector a analizar
		  wf._n_orig=UART_RX_items;
		  while(FT_String_ND(UART_RX_vect_hld,&wf._n_orig,"ready",&wf._n_fcomp,wf._uartRCVD_tok,&wf._n_tok,&wf._n_fcomp,&wf._id_conn,&wf._overflowVector,FIND)!=1)
		  {
			  wf._n_orig=UART_RX_items;
				  if (ESP_ticks>=5000)
					 {
						 ESP_InitF=1;
						 break;
					 }
		  }

		  if (ESP_ticks<5000)
		  {
			  ESP_REinit=10;	//Condición de salida
			  ESP_ticks=0;
		  }
		  else
		  {
			  ESP_REinit++;		//Conteo de la cantidad de veces que se reinicia el ciclo
			  ESP_ticks=0;
		  }

	 } while (ESP_REinit<=5);

	  if(ESP_REinit==10)
	  {
		  return(1);
	  }
	  else
	  {
		  return(0);
	  }
}

int ITM0_Write( char *ptr, int len)
{
 int DataIdx;

  for(DataIdx=0; DataIdx<len; DataIdx++)
  {
    ITM_SendChar(*ptr++);
  }
  return len;
}

/* USER CODE END 4 */

void Error_Handler(void)
{
  __disable_irq();
  while (1)
  {
  }
}
